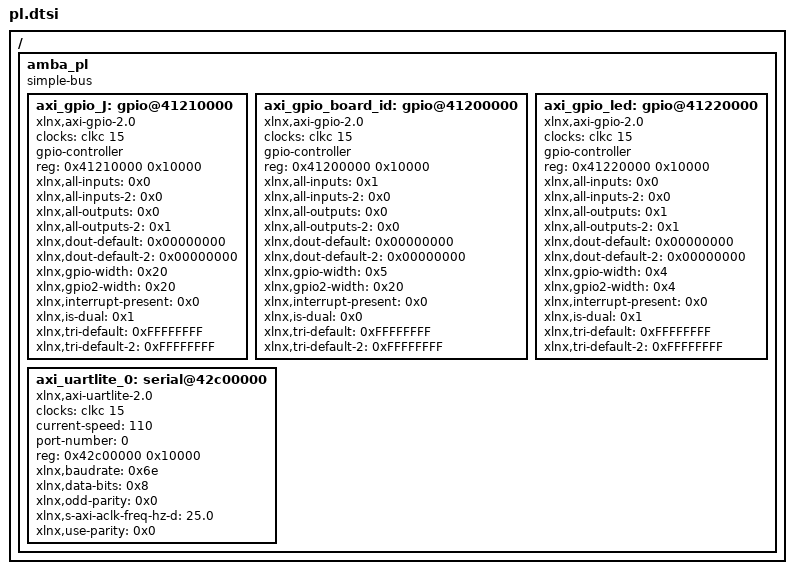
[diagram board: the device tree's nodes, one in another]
/*
 * CAUTION: This file is automatically generated by Xilinx.
 * Version: XSCT 2019.1
 * Today is: Thu Jul 17 16:31:11 2025
 */


/ {
	amba_pl: amba_pl {
		#address-cells = <1>;
		#size-cells = <1>;
		compatible = "simple-bus";
		ranges ;
		axi_gpio_J: gpio@41210000 {
			#gpio-cells = <3>;
			clock-names = "s_axi_aclk";
			clocks = <&clkc 15>;
			compatible = "xlnx,axi-gpio-2.0", "xlnx,xps-gpio-1.00.a";
			gpio-controller ;
			reg = <0x41210000 0x10000>;
			xlnx,all-inputs = <0x0>;
			xlnx,all-inputs-2 = <0x0>;
			xlnx,all-outputs = <0x0>;
			xlnx,all-outputs-2 = <0x1>;
			xlnx,dout-default = <0x00000000>;
			xlnx,dout-default-2 = <0x00000000>;
			xlnx,gpio-width = <0x20>;
			xlnx,gpio2-width = <0x20>;
			xlnx,interrupt-present = <0x0>;
			xlnx,is-dual = <0x1>;
			xlnx,tri-default = <0xFFFFFFFF>;
			xlnx,tri-default-2 = <0xFFFFFFFF>;
		};
		axi_gpio_board_id: gpio@41200000 {
			#gpio-cells = <3>;
			clock-names = "s_axi_aclk";
			clocks = <&clkc 15>;
			compatible = "xlnx,axi-gpio-2.0", "xlnx,xps-gpio-1.00.a";
			gpio-controller ;
			reg = <0x41200000 0x10000>;
			xlnx,all-inputs = <0x1>;
			xlnx,all-inputs-2 = <0x0>;
			xlnx,all-outputs = <0x0>;
			xlnx,all-outputs-2 = <0x0>;
			xlnx,dout-default = <0x00000000>;
			xlnx,dout-default-2 = <0x00000000>;
			xlnx,gpio-width = <0x5>;
			xlnx,gpio2-width = <0x20>;
			xlnx,interrupt-present = <0x0>;
			xlnx,is-dual = <0x0>;
			xlnx,tri-default = <0xFFFFFFFF>;
			xlnx,tri-default-2 = <0xFFFFFFFF>;
		};
		axi_gpio_led: gpio@41220000 {
			#gpio-cells = <3>;
			clock-names = "s_axi_aclk";
			clocks = <&clkc 15>;
			compatible = "xlnx,axi-gpio-2.0", "xlnx,xps-gpio-1.00.a";
			gpio-controller ;
			reg = <0x41220000 0x10000>;
			xlnx,all-inputs = <0x0>;
			xlnx,all-inputs-2 = <0x0>;
			xlnx,all-outputs = <0x1>;
			xlnx,all-outputs-2 = <0x1>;
			xlnx,dout-default = <0x00000000>;
			xlnx,dout-default-2 = <0x00000000>;
			xlnx,gpio-width = <0x4>;
			xlnx,gpio2-width = <0x4>;
			xlnx,interrupt-present = <0x0>;
			xlnx,is-dual = <0x1>;
			xlnx,tri-default = <0xFFFFFFFF>;
			xlnx,tri-default-2 = <0xFFFFFFFF>;
		};
		axi_uartlite_0: serial@42c00000 {
			clock-names = "s_axi_aclk";
			clocks = <&clkc 15>;
			compatible = "xlnx,axi-uartlite-2.0", "xlnx,xps-uartlite-1.00.a";
			current-speed = <110>;
			device_type = "serial";
			port-number = <0>;
			reg = <0x42c00000 0x10000>;
			xlnx,baudrate = <0x6e>;
			xlnx,data-bits = <0x8>;
			xlnx,odd-parity = <0x0>;
			xlnx,s-axi-aclk-freq-hz-d = "25.0";
			xlnx,use-parity = <0x0>;
		};
	};
};
